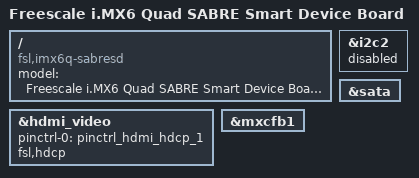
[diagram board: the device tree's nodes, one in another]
/*
 * Copyright 2012 Freescale Semiconductor, Inc.
 * Copyright 2011 Linaro Ltd.
 *
 * The code contained herein is licensed under the GNU General Public
 * License. You may obtain a copy of the GNU General Public License
 * Version 2 or later at the following locations:
 *
 * http://www.opensource.org/licenses/gpl-license.html
 * http://www.gnu.org/copyleft/gpl.html
 */

/dts-v1/;

#include "imx6q.dtsi"
#include "imx6qdl-sabresd.dtsi"

/ {
	model = "Freescale i.MX6 Quad SABRE Smart Device Board";
	compatible = "fsl,imx6q-sabresd", "fsl,imx6q";
};

&hdmi_video {
        pinctrl-names = "default";
        pinctrl-0 = <&pinctrl_hdmi_hdcp_1>;
        fsl,hdcp;
};

&i2c2 {
        status = "disable";
};

&mxcfb1 {
	status = "okay";
};

&sata {
	status = "okay";
};
